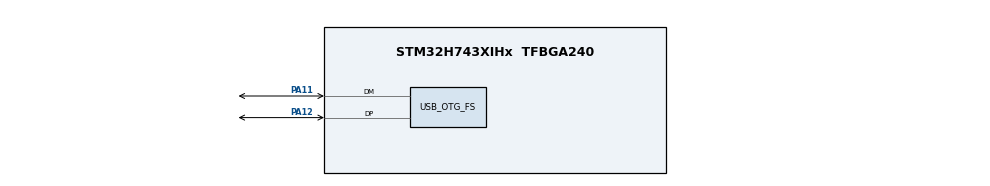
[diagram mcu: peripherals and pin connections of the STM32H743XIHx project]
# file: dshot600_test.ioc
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CORTEX_M7.default_mode_Activation=1
Dma.Request0=TIM3_UP
Dma.TIM3_UP.0.Direction=DMA_MEMORY_TO_PERIPH
Dma.TIM3_UP.0.EventEnable=DISABLE
Dma.TIM3_UP.0.FIFOMode=DMA_FIFOMODE_DISABLE
Dma.TIM3_UP.0.Instance=DMA1_Stream0
Dma.TIM3_UP.0.MemDataAlignment=DMA_MDATAALIGN_WORD
Dma.TIM3_UP.0.MemInc=DMA_MINC_ENABLE
Dma.TIM3_UP.0.Mode=DMA_NORMAL
Dma.TIM3_UP.0.PeriphDataAlignment=DMA_PDATAALIGN_WORD
Dma.TIM3_UP.0.PeriphInc=DMA_PINC_DISABLE
Dma.TIM3_UP.0.Polarity=HAL_DMAMUX_REQ_GEN_RISING
Dma.TIM3_UP.0.Priority=DMA_PRIORITY_HIGH
Dma.TIM3_UP.0.RequestNumber=1
Dma.TIM3_UP.0.SignalID=NONE
Dma.TIM3_UP.0.SyncEnable=DISABLE
Dma.TIM3_UP.0.SyncPolarity=HAL_DMAMUX_SYNC_NO_EVENT
Dma.TIM3_UP.0.SyncRequestNumber=1
Dma.TIM3_UP.0.SyncSignalID=NONE
Mcu.Family=STM32H7
Mcu.Name=STM32H743XIHx
Mcu.Package=TFBGA240
NVIC.DMA1_Stream0_IRQn=true\:5\:0\:false\:false\:true\:true\:false\:true
NVIC.OTG_FS_IRQn=true\:6\:0\:false\:false\:true\:true\:true\:true
NVIC.PriorityGroup=NVIC_PRIORITYGROUP_4
NVIC.TIM6_DAC_IRQn=true\:15\:0\:false\:false\:true\:false\:false\:true
NVIC.TimeBase=TIM6_DAC_IRQn
NVIC.TimeBaseIP=TIM6
PA11.Mode=Device_Only
PA11.Signal=USB_OTG_FS_DM
PA12.Mode=Device_Only
PA12.Signal=USB_OTG_FS_DP
PA6.GPIO_Speed=GPIO_SPEED_FREQ_VERY_HIGH
PA6.Signal=S_TIM3_CH1
PA7.GPIO_Speed=GPIO_SPEED_FREQ_VERY_HIGH
PA7.Signal=S_TIM3_CH2
PB0.GPIO_Speed=GPIO_SPEED_FREQ_VERY_HIGH
PB0.Signal=S_TIM3_CH3
PB1.GPIO_Speed=GPIO_SPEED_FREQ_VERY_HIGH
PB1.Signal=S_TIM3_CH4
PH0-OSC_IN\ (PH0).Mode=HSE-External-Oscillator
PH0-OSC_IN\ (PH0).Signal=RCC_OSC_IN
PH1-OSC_OUT\ (PH1).Mode=HSE-External-Oscillator
PH1-OSC_OUT\ (PH1).Signal=RCC_OSC_OUT
ProjectManager.HeapSize=0x200
ProjectManager.StackSize=0x400
ProjectManager.TargetToolchain=STM32CubeIDE
RCC.ADCFreq_Value=129000000
RCC.APB1Freq_Value=112500000
RCC.APB2Freq_Value=112500000
RCC.APB3Freq_Value=112500000
RCC.APB4Freq_Value=112500000
RCC.CortexFreq_Value=225000000
RCC.D1PPRE=RCC_APB3_DIV2
RCC.D2PPRE1=RCC_APB1_DIV2
RCC.D2PPRE2=RCC_APB2_DIV2
RCC.D3PPRE=RCC_APB4_DIV2
RCC.DIVM1=4
RCC.DIVN1=28
RCC.DIVQ1=5
RCC.HCLKFreq_Value=225000000
RCC.PLL2FRACN=0
RCC.PLL3FRACN=0
RCC.PLLFRACN=1024
RCC.SYSCLKFreq_VALUE=225000000
RCC.SYSCLKSource=RCC_SYSCLKSOURCE_PLLCLK
RCC.USBCLockSelection=RCC_USBCLKSOURCE_HSI48
RCC.USBFreq_Value=48000000
SH.S_TIM3_CH1.0=TIM3_CH1
SH.S_TIM3_CH2.0=TIM3_CH2
SH.S_TIM3_CH3.0=TIM3_CH3
SH.S_TIM3_CH4.0=TIM3_CH4
TIM3.Channel-PWM\ Generation1\ CH1=TIM_CHANNEL_1
TIM3.Channel-PWM\ Generation2\ CH2=TIM_CHANNEL_2
TIM3.Channel-PWM\ Generation3\ CH3=TIM_CHANNEL_3
TIM3.Channel-PWM\ Generation4\ CH4=TIM_CHANNEL_4
TIM3.Period=99
TIM3.Prescaler=0
TIM3.Pulse-PWM\ Generation1\ CH1=0
TIM3.Pulse-PWM\ Generation2\ CH2=0
TIM3.Pulse-PWM\ Generation3\ CH3=0
TIM3.Pulse-PWM\ Generation4\ CH4=0
USB_DEVICE.CLASS_NAME_FS=CDC
USB_DEVICE.VirtualMode-CDC_FS=Cdc
USB_DEVICE.VirtualModeFS=Cdc_FS
USB_OTG_FS.VirtualMode=Device_Only
VP_MEMORYMAP_VS_MEMORYMAP.Mode=CurAppReg
VP_SYS_VS_tim6.Mode=TIM6
VP_TIM3_VS_ClockSourceINT.Mode=Internal
VP_USB_DEVICE_VS_USB_DEVICE_CDC_FS.Mode=CDC_FS
board=custom

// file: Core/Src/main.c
/* USER CODE BEGIN Header */
/**
  ******************************************************************************
  * @file           : main.c
  * @brief          : Main program body
  ******************************************************************************
  * @attention
  *
  * Copyright (c) 2026 STMicroelectronics.
  * All rights reserved.
  *
  * This software is licensed under terms that can be found in the LICENSE file
  * in the root directory of this software component.
  * If no LICENSE file comes with this software, it is provided AS-IS.
  *
  ******************************************************************************
  */
/* USER CODE END Header */
#include "main.h"

/* USER CODE BEGIN Includes */
#include "dshot_bench.h"
#include "usb_log.h"

/* USER CODE END Includes */

TIM_HandleTypeDef htim3;
DMA_HandleTypeDef hdma_tim3_up;

void SystemClock_Config(void);
static void MPU_Config(void);
static void MX_GPIO_Init(void);
static void MX_DMA_Init(void);
static void MX_TIM3_Init(void);

int main(void)
{

  /* MPU Configuration--------------------------------------------------------*/
  MPU_Config();

  /* MCU Configuration--------------------------------------------------------*/

  /* Reset of all peripherals, Initializes the Flash interface and the Systick. */
  HAL_Init();

  /* Configure the system clock */
  SystemClock_Config();

  /* Initialize all configured peripherals */
  MX_GPIO_Init();
  MX_DMA_Init();
  MX_TIM3_Init();
  /* USER CODE BEGIN 2 */
  UsbLog_Init();
  DshotBench_Init(&htim3);

  /* USER CODE END 2 */

  /* Infinite loop */
  while (1)
  {

    /* USER CODE BEGIN 3 */
    DshotBench_Step();
    UsbLog_Step();
  }
  /* USER CODE END 3 */
}

void SystemClock_Config(void)
{
  RCC_OscInitTypeDef RCC_OscInitStruct = {0};
  RCC_ClkInitTypeDef RCC_ClkInitStruct = {0};

  /** Supply configuration update enable
  */
  HAL_PWREx_ConfigSupply(PWR_LDO_SUPPLY);

  /** Configure the main internal regulator output voltage
  */
  __HAL_PWR_VOLTAGESCALING_CONFIG(PWR_REGULATOR_VOLTAGE_SCALE2);

  while(!__HAL_PWR_GET_FLAG(PWR_FLAG_VOSRDY)) {}

  /** Initializes the RCC Oscillators according to the specified parameters
  * in the RCC_OscInitTypeDef structure.
  */
  RCC_OscInitStruct.OscillatorType = RCC_OSCILLATORTYPE_HSI;
  RCC_OscInitStruct.HSIState = RCC_HSI_DIV1;
  RCC_OscInitStruct.HSICalibrationValue = RCC_HSICALIBRATION_DEFAULT;
  RCC_OscInitStruct.PLL.PLLState = RCC_PLL_ON;
  RCC_OscInitStruct.PLL.PLLSource = RCC_PLLSOURCE_HSI;
  RCC_OscInitStruct.PLL.PLLM = 4;
  RCC_OscInitStruct.PLL.PLLN = 28;
  RCC_OscInitStruct.PLL.PLLP = 2;
  RCC_OscInitStruct.PLL.PLLQ = 5;
  RCC_OscInitStruct.PLL.PLLR = 2;
  RCC_OscInitStruct.PLL.PLLRGE = RCC_PLL1VCIRANGE_3;
  RCC_OscInitStruct.PLL.PLLVCOSEL = RCC_PLL1VCOWIDE;
  RCC_OscInitStruct.PLL.PLLFRACN = 1024;
  if (HAL_RCC_OscConfig(&RCC_OscInitStruct) != HAL_OK)
  {
    Error_Handler();
  }

  /** Initializes the CPU, AHB and APB buses clocks
  */
  RCC_ClkInitStruct.ClockType = RCC_CLOCKTYPE_HCLK|RCC_CLOCKTYPE_SYSCLK
                              |RCC_CLOCKTYPE_PCLK1|RCC_CLOCKTYPE_PCLK2
                              |RCC_CLOCKTYPE_D3PCLK1|RCC_CLOCKTYPE_D1PCLK1;
  RCC_ClkInitStruct.SYSCLKSource = RCC_SYSCLKSOURCE_PLLCLK;
  RCC_ClkInitStruct.SYSCLKDivider = RCC_SYSCLK_DIV1;
  RCC_ClkInitStruct.AHBCLKDivider = RCC_HCLK_DIV1;
  RCC_ClkInitStruct.APB3CLKDivider = RCC_APB3_DIV2;
  RCC_ClkInitStruct.APB1CLKDivider = RCC_APB1_DIV2;
  RCC_ClkInitStruct.APB2CLKDivider = RCC_APB2_DIV2;
  RCC_ClkInitStruct.APB4CLKDivider = RCC_APB4_DIV2;

  if (HAL_RCC_ClockConfig(&RCC_ClkInitStruct, FLASH_LATENCY_4) != HAL_OK)
  {
    Error_Handler();
  }
}

static void MX_TIM3_Init(void)
{

  TIM_ClockConfigTypeDef sClockSourceConfig = {0};
  TIM_MasterConfigTypeDef sMasterConfig = {0};

  htim3.Instance = TIM3;
  htim3.Init.Prescaler = 0;
  htim3.Init.CounterMode = TIM_COUNTERMODE_UP;
  htim3.Init.Period = 99;
  htim3.Init.ClockDivision = TIM_CLOCKDIVISION_DIV1;
  htim3.Init.AutoReloadPreload = TIM_AUTORELOAD_PRELOAD_DISABLE;
  if (HAL_TIM_Base_Init(&htim3) != HAL_OK)
  {
    Error_Handler();
  }
  sClockSourceConfig.ClockSource = TIM_CLOCKSOURCE_INTERNAL;
  if (HAL_TIM_ConfigClockSource(&htim3, &sClockSourceConfig) != HAL_OK)
  {
    Error_Handler();
  }
  sMasterConfig.MasterOutputTrigger = TIM_TRGO_RESET;
  sMasterConfig.MasterSlaveMode = TIM_MASTERSLAVEMODE_DISABLE;
  if (HAL_TIMEx_MasterConfigSynchronization(&htim3, &sMasterConfig) != HAL_OK)
  {
    Error_Handler();
  }

}

static void MX_DMA_Init(void)
{

  /* DMA controller clock enable */
  __HAL_RCC_DMA1_CLK_ENABLE();

  /* DMA interrupt init */
  /* DMA1_Stream0_IRQn interrupt configuration */
  HAL_NVIC_SetPriority(DMA1_Stream0_IRQn, 5, 0);
  HAL_NVIC_EnableIRQ(DMA1_Stream0_IRQn);

}

static void MX_GPIO_Init(void)
{

  /* GPIO Ports Clock Enable */
  __HAL_RCC_GPIOH_CLK_ENABLE();
  __HAL_RCC_GPIOA_CLK_ENABLE();
  __HAL_RCC_GPIOB_CLK_ENABLE();

}

 /* MPU Configuration */

void MPU_Config(void)
{
  MPU_Region_InitTypeDef MPU_InitStruct = {0};

  /* Disables the MPU */
  HAL_MPU_Disable();

  /** Initializes and configures the Region and the memory to be protected
  */
  MPU_InitStruct.Enable = MPU_REGION_ENABLE;
  MPU_InitStruct.Number = MPU_REGION_NUMBER0;
  MPU_InitStruct.BaseAddress = 0x0;
  MPU_InitStruct.Size = MPU_REGION_SIZE_4GB;
  MPU_InitStruct.SubRegionDisable = 0x87;
  MPU_InitStruct.TypeExtField = MPU_TEX_LEVEL0;
  MPU_InitStruct.AccessPermission = MPU_REGION_NO_ACCESS;
  MPU_InitStruct.DisableExec = MPU_INSTRUCTION_ACCESS_DISABLE;
  MPU_InitStruct.IsShareable = MPU_ACCESS_SHAREABLE;
  MPU_InitStruct.IsCacheable = MPU_ACCESS_NOT_CACHEABLE;
  MPU_InitStruct.IsBufferable = MPU_ACCESS_NOT_BUFFERABLE;

  HAL_MPU_ConfigRegion(&MPU_InitStruct);
  /* Enables the MPU */
  HAL_MPU_Enable(MPU_PRIVILEGED_DEFAULT);

}

void HAL_TIM_PeriodElapsedCallback(TIM_HandleTypeDef *htim)
{
  if (htim->Instance == TIM6)
  {
    HAL_IncTick();
  }
}

void Error_Handler(void)
{
  __disable_irq();
  while (1)
  {
  }
}
